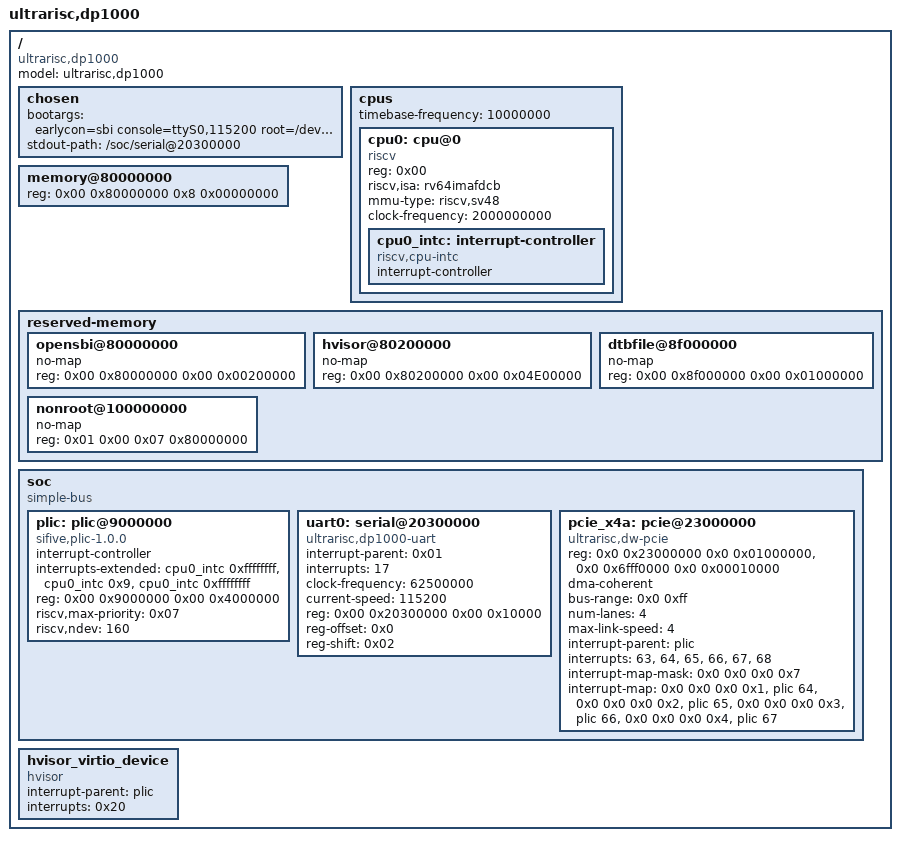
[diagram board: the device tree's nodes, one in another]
/dts-v1/;

/ {
	#address-cells = <0x02>;
	#size-cells = <0x02>;
	compatible = "ultrarisc,dp1000";
	model = "ultrarisc,dp1000";

	chosen {
		bootargs = "earlycon=sbi console=ttyS0,115200 root=/dev/nvme0n1p2 rootfstype=ext4 rw rootwait init=/bin/bash";
		stdout-path = "/soc/serial@20300000";
	};

	cpus {
		#address-cells = <0x01>;
		#size-cells = <0x00>;
		timebase-frequency = <10000000>;

    	cpu0: cpu@0 {
			device_type = "cpu";
			reg = <0x00>;
			status = "okay";
			compatible = "riscv";
			riscv,isa = "rv64imafdcb";
			mmu-type = "riscv,sv48";
			clock-frequency = <2000000000>;
			cpu0_intc:interrupt-controller {
				#address-cells = <0x01>;
				interrupt-controller;
				compatible = "riscv,cpu-intc";
				#interrupt-cells = <0x01>;
			};
		};
	};

	memory@80000000 {
		device_type = "memory";
		reg = <0x00 0x80000000 0x8 0x00000000>;
	};

    reserved-memory {
		#address-cells = <0x02>;
		#size-cells = <0x02>;
		ranges;

        // 0x8000_0000 - 0x8500_0000 is reserverd for low-level software
		opensbi@80000000 {
			no-map;
			reg = <0x00 0x80000000 0x00 0x00200000>;
		};

		hvisor@80200000 {
			no-map;
			reg = <0x00 0x80200000 0x00 0x04E00000>;
		};

        // zone0's dtb is located here
		dtbfile@8f000000 {
			no-map;
			reg = <0x00 0x8f000000 0x00 0x01000000>;
		};

        // non-root area, here 30GB
        nonroot@100000000 {
			no-map;
			reg = <0x01 0x00 0x07 0x80000000>;
		};
	};

	soc {
		#address-cells = <0x02>;
		#size-cells = <0x02>;
		compatible = "simple-bus";
		ranges;

		plic: plic@9000000 {
			#interrupt-cells = <1>;
			#address-cells = <0>;
			phandle = <0x01>;
			compatible = "sifive,plic-1.0.0";
			interrupt-controller;
			interrupts-extended = <&cpu0_intc 0xffffffff>, <&cpu0_intc 0x9>, <&cpu0_intc 0xffffffff>;
			reg = <0x00 0x9000000 0x00 0x4000000>;
			riscv,max-priority = <0x07>;
			riscv,ndev = <160>;
		};

		uart0: serial@20300000 {
			interrupt-parent = <0x01>;
			interrupts = <17>;
			clock-frequency = <62500000>;
			current-speed = <115200>;
			reg = <0x00 0x20300000 0x00 0x10000>;
			compatible = "ultrarisc,dp1000-uart","ns16550";
			reg-offset = <0x0>;
			reg-shift = <0x02>;
		};

		pcie_x4a: pcie@23000000 {
			compatible = "ultrarisc,dw-pcie";
			#address-cells = <3>;
			#size-cells = <2>;
			#interrupt-cells = <1>;
			reg = <0x0 0x23000000 0x0 0x01000000>, /* IP registers */
			      <0x0 0x6fff0000 0x0 0x00010000>; /* Configuration space */
			reg-names = "dbi", "config";
			device_type = "pci";
			dma-coherent;
			bus-range = <0x0 0xff>;
			num-lanes = <4>;
			ranges = <0x81000000  0x0 0x6fbf0000  0x0 0x6fbf0000  0x0 0x00400000>,
				 <0x82000000  0x0 0x60000000  0x0 0x60000000  0x0 0x0fbf0000>,
				 <0xc3000000 0x80 0x00000000 0x80 0x00000000  0xd 0x00000000>;
			max-link-speed = <4>;
			interrupt-parent = <&plic>;
			interrupts = <63>, <64>, <65>, <66>, <67>, <68>;
			interrupt-names = "msi", "inta", "intb", "intc", "intd", "aer";
			interrupt-map-mask = <0x0 0x0 0x0 0x7>;
			interrupt-map = <0x0 0x0 0x0 0x1 &plic 64>,
					<0x0 0x0 0x0 0x2 &plic 65>,
					<0x0 0x0 0x0 0x3 &plic 66>,
					<0x0 0x0 0x0 0x4 &plic 67>;
		};
	};

    hvisor_virtio_device {
		compatible = "hvisor";
    	interrupt-parent = <&plic>;
    	interrupts = <0x20>;
	};
};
